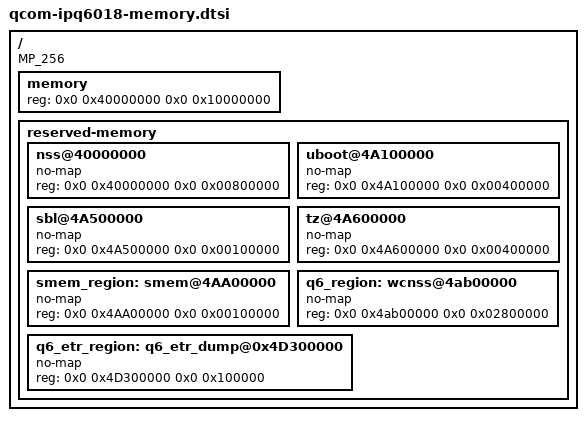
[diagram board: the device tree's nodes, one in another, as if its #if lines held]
/*
 * Copyright (c) 2018-2019, The Linux Foundation. All rights reserved.
 *
 * Permission to use, copy, modify, and/or distribute this software for any
 * purpose with or without fee is hereby granted, provided that the above
 * copyright notice and this permission notice appear in all copies.
 *
 * THE SOFTWARE IS PROVIDED "AS IS" AND THE AUTHOR DISCLAIMS ALL WARRANTIES
 * WITH REGARD TO THIS SOFTWARE INCLUDING ALL IMPLIED WARRANTIES OF
 * MERCHANTABILITY AND FITNESS. IN NO EVENT SHALL THE AUTHOR BE LIABLE FOR
 * ANY SPECIAL, DIRECT, INDIRECT, OR CONSEQUENTIAL DAMAGES OR ANY DAMAGES
 * WHATSOEVER RESULTING FROM LOSS OF USE, DATA OR PROFITS, WHETHER IN AN
 * ACTION OF CONTRACT, NEGLIGENCE OR OTHER TORTIOUS ACTION, ARISING OUT OF
 * OR IN CONNECTION WITH THE USE OR PERFORMANCE OF THIS SOFTWARE.
 */


/ {
#ifdef __IPQ_MEM_PROFILE_256_MB__
	MP_256;
#elif __IPQ_MEM_PROFILE_512_MB__
	MP_512;
#endif

	/*		   256 MB Profile
	 * +=========+==============+========================+
	 * |        |              |                         |
	 * | Region | Start Offset |          Size           |
	 * |        |              |                         |
	 * +--------+--------------+-------------------------+
	 * |        |              |                         |
	 * |  NSS   |  0x40000000  |          8MB            |
	 * |        |              |                         |
	 * +--------+--------------+-------------------------+
	 * |        |              |                         |
	 * |        |              |                         |
	 * |        |              |                         |
	 * |        |              |                         |
	 * | Linux  |  0x41000000  |         153MB           |
	 * |        |              |                         |
	 * |        |              |                         |
	 * |        |              |                         |
	 * +--------+--------------+-------------------------+
	 * |        |              |                         |
	 * | uboot  |  0x4A100000  |           4MB           |
	 * |        |              |                         |
	 * +--------+--------------+-------------------------+
	 * |  SBL   |  0x4A500000  |           1MB           |
	 * +--------+--------------+-------------------------+
	 * |        |              |                         |
	 * | TZ+HYP |  0x4A600000  |           4MB           |
	 * |        |              |                         |
	 * +--------+--------------+-------------------------+
	 * |  smem  |  0x4AA00000  |           1MB           |
	 * +--------+--------------+-------------------------+
	 * |        |              |                         |
	 * |        |              |                         |
	 * | WLAN   |              |                         |
	 * |   Q6   |  0x4AB00000  |          40MB           |
	 * |        |              |                         |
	 * |        |              |                         |
	 * +--------+--------------+-------------------------+
	 * | WLAN   |              |                         |
	 * | Q6 ETR |  0x4D300000  |          1MB            |
	 * | Region |              |                         |
	 * +=================================================+
	 * |                                                 |
	 * |                                                 |
	 * |                                                 |
	 * |            44MB memory for Linux                |
	 * |                                                 |
	 * |                                                 |
	 * |                                                 |
	 * +=================================================+
	 */

#ifdef __IPQ_MEM_PROFILE_256_MB__
	memory {
		device_type = "memory";
		reg = <0x0 0x40000000 0x0 0x10000000>;
	};

	reserved-memory {
		#address-cells = <2>;
		#size-cells = <2>;
		ranges;

		nss@40000000 {
			no-map;
			reg = <0x0 0x40000000 0x0 0x00800000>;
		};

		uboot@4A100000 {
			no-map;
			reg = <0x0 0x4A100000 0x0 0x00400000>;
		};

		sbl@4A500000 {
			no-map;
			reg = <0x0 0x4A500000 0x0 0x00100000>;
		};

		tz@4A600000 {
			no-map;
			reg = <0x0 0x4A600000 0x0 0x00400000>;
		};

		smem_region:smem@4AA00000 {
			no-map;
			reg = <0x0 0x4AA00000 0x0 0x00100000>;
		};

		q6_region: wcnss@4ab00000 {
			no-map;
			reg = <0x0 0x4ab00000 0x0 0x02800000>;
		};

		q6_etr_region: q6_etr_dump@0x4D300000 {
			no-map;
			reg = <0x0 0x4D300000 0x0 0x100000>;
		};
	};

	/*		    512 MB Profile
	 * +=========+==============+========================+
	 * |        |              |                         |
	 * | Region | Start Offset |          Size           |
	 * |        |              |                         |
	 * +--------+--------------+-------------------------+
	 * |        |              |                         |
	 * |  NSS   |  0x40000000  |          16MB           |
	 * |        |              |                         |
	 * +--------+--------------+-------------------------+
	 * |        |              |                         |
	 * |        |              |                         |
	 * |        |              |                         |
	 * |        |              |                         |
	 * | Linux  |  0x41000000  |         145MB           |
	 * |        |              |                         |
	 * |        |              |                         |
	 * |        |              |                         |
	 * +--------+--------------+-------------------------+
	 * |        |              |                         |
	 * | uboot  |  0x4A100000  |           4MB           |
	 * |        |              |                         |
	 * +--------+--------------+-------------------------+
	 * |  SBL   |  0x4A500000  |           1MB           |
	 * +--------+--------------+-------------------------+
	 * |        |              |                         |
	 * | TZ+HYP |  0x4A600000  |           4MB           |
	 * |        |              |                         |
	 * +--------+--------------+-------------------------+
	 * |  smem  |  0x4AA00000  |           1MB           |
	 * +--------+--------------+-------------------------+
	 * |        |              |                         |
	 * |        |              |                         |
	 * | WLAN   |              |                         |
	 * |   Q6   |  0x4AB00000  |          55MB           |
	 * |        |              |                         |
	 * |        |              |                         |
	 * +--------+--------------+-------------------------+
	 * | WLAN   |              |                         |
	 * | Q6 ETR |  0x4E200000  |           1MB           |
	 * | Region |              |                         |
	 * +=================================================+
	 * |                                                 |
	 * |                                                 |
	 * |                                                 |
	 * |            285MB memory for Linux               |
	 * |                                                 |
	 * |                                                 |
	 * |                                                 |
	 * +=================================================+
	 */

#elif __IPQ_MEM_PROFILE_512_MB__
	memory {
		device_type = "memory";
		reg = <0x0 0x40000000 0x0 0x20000000>;
	};

	reserved-memory {
		#address-cells = <2>;
		#size-cells = <2>;
		ranges;

		nss@40000000 {
			no-map;
			reg = <0x0 0x40000000 0x0 0x01000000>;
		};

		uboot@4A100000 {
			no-map;
			reg = <0x0 0x4A100000 0x0 0x00400000>;
		};

		sbl@4A500000 {
			no-map;
			reg = <0x0 0x4A500000 0x0 0x00100000>;
		};

		tz@4A600000 {
			no-map;
			reg = <0x0 0x4A600000 0x0 0x00400000>;
		};

		smem_region:smem@4AA00000 {
			no-map;
			reg = <0x0 0x4AA00000 0x0 0x00100000>;
		};

		q6_region: wcnss@4ab00000 {
			no-map;
			reg = <0x0 0x4ab00000 0x0 0x03700000>;
		};

		q6_etr_region: q6_etr_dump@0x4D300000 {
			no-map;
			reg = <0x0 0x4E200000 0x0 0x100000>;
		};
	};

	/*		  Default Profile
	 * +=========+==============+========================+
	 * |        |              |                         |
	 * | Region | Start Offset |          Size           |
	 * |        |              |                         |
	 * +--------+--------------+-------------------------+
	 * |        |              |                         |
	 * |  NSS   |  0x40000000  |          16MB           |
	 * |        |              |                         |
	 * +--------+--------------+-------------------------+
	 * |        |              |                         |
	 * |        |              |                         |
	 * |        |              |                         |
	 * |        |              |                         |
	 * | Linux  |  0x41000000  |         145MB           |
	 * |        |              |                         |
	 * |        |              |                         |
	 * |        |              |                         |
	 * +--------+--------------+-------------------------+
	 * |        |              |                         |
	 * | uboot  |  0x4A100000  |           4MB           |
	 * |        |              |                         |
	 * +--------+--------------+-------------------------+
	 * |  SBL   |  0x4A500000  |           1MB           |
	 * +--------+--------------+-------------------------+
	 * |        |              |                         |
	 * | TZ+HYP |  0x4A600000  |           4MB           |
	 * |        |              |                         |
	 * +--------+--------------+-------------------------+
	 * |  smem  |  0x4AA00000  |           1MB           |
	 * +--------+--------------+-------------------------+
	 * |        |              |                         |
	 * |        |              |                         |
	 * | WLAN   |              |                         |
	 * |   Q6   |  0x4AB00000  |          85MB           |
	 * |        |              |                         |
	 * |        |              |                         |
	 * +--------+--------------+-------------------------+
	 * | WLAN   |              |                         |
	 * | Q6 ETR |  0x50000000  |           1MB           |
	 * | Region |              |                         |
	 * +=================================================+
	 * |                                                 |
	 * |                                                 |
	 * |                                                 |
	 * |            767MB memory for Linux               |
	 * |                                                 |
	 * |                                                 |
	 * |                                                 |
	 * +=================================================+
	 */

#else
	memory {
		device_type = "memory";
		reg = <0x0 0x40000000 0x0 0x40000000>;
	};

	reserved-memory {
		#address-cells = <2>;
		#size-cells = <2>;
		ranges;

		nss@40000000 {
			no-map;
			reg = <0x0 0x40000000 0x0 0x01000000>;
		};

		uboot@4A100000 {
			no-map;
			reg = <0x0 0x4A100000 0x0 0x00400000>;
		};

		sbl@4A500000 {
			no-map;
			reg = <0x0 0x4A500000 0x0 0x00100000>;
		};

		tz@4A600000 {
			no-map;
			reg = <0x0 0x4A600000 0x0 0x00400000>;
		};

		smem_region:smem@4AA00000 {
			no-map;
			reg = <0x0 0x4AA00000 0x0 0x00100000>;
		};

		q6_region: wcnss@4ab00000 {
			no-map;
			reg = <0x0 0x4ab00000 0x0 0x05500000>;
		};

		q6_etr_region: q6_etr_dump@0x4D300000 {
			no-map;
			reg = <0x0 0x50000000 0x0 0x100000>;
		};
	};
#endif
};
